# MB9AF31xK register map
Vendor: Cypress; File version: 2.1
CPU: CM3 r2p1, little endian, MPU, no FPU, 4 interrupt priority bits
Registers are 32-bit, read-write, reset 0x0 unless marked. A register's access mark holds for its fields unless they carry their own. Offsets are from the block's base; [hi:lo] are bit positions; {n}, {i} and the like mark numbered series.

## CRTRIM — CR Trimming Registers
Base 0x4002E000
0x00 MCR_PSR 8-bit reset 0x1 — High-speed CR oscillation Frequency Division Setup Register [BHW]
  [1:0] CSR — High-speed CR oscillation frequency division ratio setting bits
0x04 MCR_FTRM 16-bit reset 0x7F — High-speed CR oscillation Frequency Trimming Register [BHW]
  [7:0] TRD — Frequency trimming setup bits
0x0C MCR_RLR reset 0x1 — High-Speed CR Oscillation Register Write-Protect Register [BHW]
  [31:0] TRMLCK — Register write-protect bits

## LVD — Low-voltage Detection
Base 0x40035000
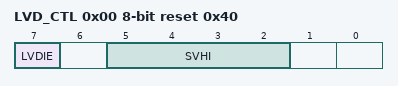
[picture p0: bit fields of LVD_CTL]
0x00 LVD_CTL 8-bit reset 0x40 — Low-voltage Detection Voltage Control Register [BHW]
  [7] LVDIE — Low-voltage detection interrupt enable bit
  [5:2] SVHI — Low-voltage detection interrupt voltage setting bits
0x04 LVD_STR 8-bit ro — Low-voltage Detection Interrupt Register [BHW]
  [7] LVDIR — Low-voltage detection interrupt bit
0x08 LVD_CLR 8-bit reset 0x80 — Low-voltage Detection Interrupt Clear Register [BHW]
  [7] LVDCL — Low-voltage detection interrupt clear bit
0x0C LVD_RLR reset 0x1 — Low-voltage Detection Voltage Protection Register [W]
  [31:0] LVDLCK — Low-voltage Detection Voltage Control Register protection bits
0x10 LVD_STR2 8-bit ro reset 0x40 — Low-voltage Detection Circuit Status Register [BHW]
  [7] LVDIRDY — Low-voltage detection interrupt status flag

## DS — Low Power Consumption Mode
Base 0x40035100
0x700 PMD_CTL 8-bit — RTC Mode Control Register [BHW]
  [0] RTCE — RTC mode control bit
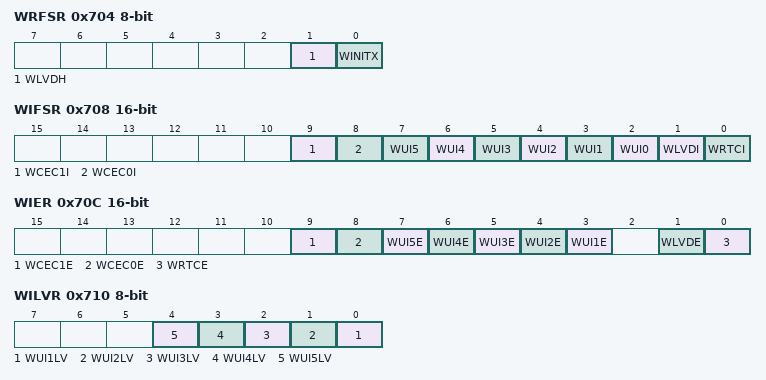
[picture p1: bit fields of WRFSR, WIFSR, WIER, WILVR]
0x704 WRFSR 8-bit — Deep Standby Return Cause Register 1 [BHW]
  [1] WLVDH — Low-voltage detection reset return bit
  [0] WINITX — INITX pin input reset return bit
0x708 WIFSR 16-bit ro — Deep Standby Return Cause Register 2 [BHW]
  [9] WCEC1I — CEC ch.1 interrupt return bit
  [8] WCEC0I — CEC ch.0 interrupt return bit
  [n+2] WUI{n} (n=0..5) — WKUP pin input return bit {n}
  [1] WLVDI — LVD interrupt return bit
  [0] WRTCI — RTC interrupt return bit
0x70C WIER 16-bit — Deep Standby Return Enable Register [BHW]
  [9] WCEC1E — HDMI-CEC/ Remote Control Reception ch.1 interrupt return enable bit
  [8] WCEC0E — HDMI-CEC/ Remote Control Reception ch.0 interrupt return enable bit
  [n+2] WUI{n}E (n=1..5) — WKUP pin input return enable bit {n}
  [1] WLVDE — LVD interrupt return enable bit
  [0] WRTCE — RTC interrupt return enable bit
0x710 WILVR 8-bit — WKUP Pin Input Level Register [BHW]
  [n-1] WUI{n}LV (n=1..5) — WKUP pin input level select bit {n}
0x714 DSRAMR 8-bit — Deep Standby RAM Retention Register [BHW]
  [1:0] SRAMR — On-chip SRAM retention control bits
{0x7FF+i} BUR{i:02} 8-bit (i=1..16) — Backup Registers from {i} [BHW]

## USBCLK — USB Clock
Base 0x40036000
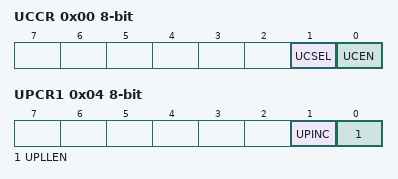
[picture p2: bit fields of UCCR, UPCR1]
0x00 UCCR 8-bit — USB Clock Control Register [BHW]
  [1] UCSEL — USB clock selection bit
  [0] UCEN — USB clock output enable bit
0x04 UPCR1 8-bit — USB-PLL Control Register 1 [BHW]
  [1] UPINC — USB-PLL input clock selection bit
  [0] UPLLEN — USB-PLL oscillation enable bit
0x08 UPCR2 8-bit — USB-PLL Control Register 2 [BHW]
  [2:0] UPOWT — USB-PLL oscillation stabilization wait time setting bit
0x0C UPCR3 8-bit — USB-PLL Control Register 3 [BHW]
  [4:0] UPLLK — Frequency division ratio (K) setting bit of the USB-PLL clock
0x10 UPCR4 8-bit reset 0x3B — USB-PLL Control Register 4 [BHW]
  [6:0] UPLLN — Frequency division ratio (N) setting bit of the USB-PLL clock
0x14 UP_STR 8-bit ro — USB-PLL Status Register [BHW]
  [0] UPRDY — USB-PLL oscillation stabilization bit
0x18 UPINT_ENR 8-bit — USB-PLL Interrupt Source Enable Register [BHW]
  [0] UPCSE — USB-PLL oscillation stabilization wait complete interrupt enable bit
0x1C UPINT_CLR 8-bit wo — USB-PLL Interrupt Source Clear Register [BHW]
  [0] UPCSC — USB-PLL oscillation stabilization interrupt source clear bit
0x20 UPINT_STR 8-bit ro — USB-PLL Interrupt Source Status Register [BHW]
  [0] UPCSI — USB-PLL interrupt source status bit
0x24 UPCR5 8-bit reset 0x4 — USB-PLL Control Register 5 [BHW]
  [3:0] UPLLM — Frequency division ratio (M) setting bit of the USB-PLL clock
0x30 USBEN0 8-bit reset 0x4 — USB Enable Register [BHW]
  [0] USBEN0 — USB enable bit
